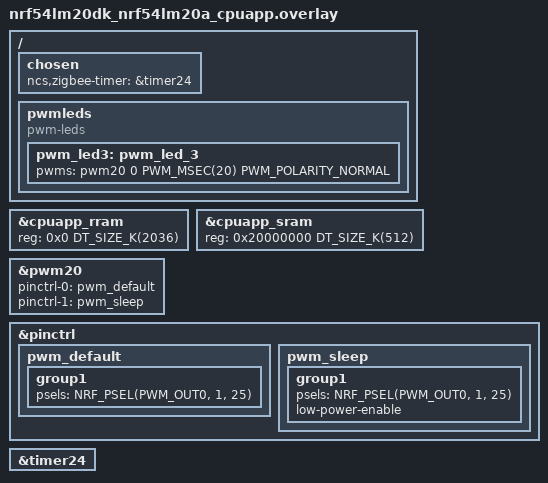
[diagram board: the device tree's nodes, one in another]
/*
 * Copyright (c) 2025 Nordic Semiconductor ASA
 *
 * SPDX-License-Identifier: LicenseRef-Nordic-5-Clause
 */

/ {
	chosen {
		ncs,zigbee-timer = &timer24;
	};

	pwmleds {
		compatible = "pwm-leds";
		pwm_led3: pwm_led_3 {
			pwms = <&pwm20 0 PWM_MSEC(20) PWM_POLARITY_NORMAL>;
		};
	};
};

// restore full RRAM and SRAM space - by default some parts are dedicated to FLRP
&cpuapp_rram {
	reg = <0x0 DT_SIZE_K(2036)>;
};

&cpuapp_sram {
	reg = <0x20000000 DT_SIZE_K(512)>;
	ranges = <0x0 0x20000000 DT_SIZE_K(512)>;
};

&pwm20 {
	status = "okay";
	pinctrl-0 = <&pwm_default>;
	pinctrl-1 = <&pwm_sleep>;
	pinctrl-names = "default", "sleep";
};

&pinctrl {
	pwm_default: pwm_default {
		group1 {
			psels = <NRF_PSEL(PWM_OUT0, 1, 25)>;
		};
	};
	pwm_sleep: pwm_sleep {
		group1 {
			psels = <NRF_PSEL(PWM_OUT0, 1, 25)>;
			low-power-enable;
		};
	};
};

&timer24 {
	status = "okay";
};
